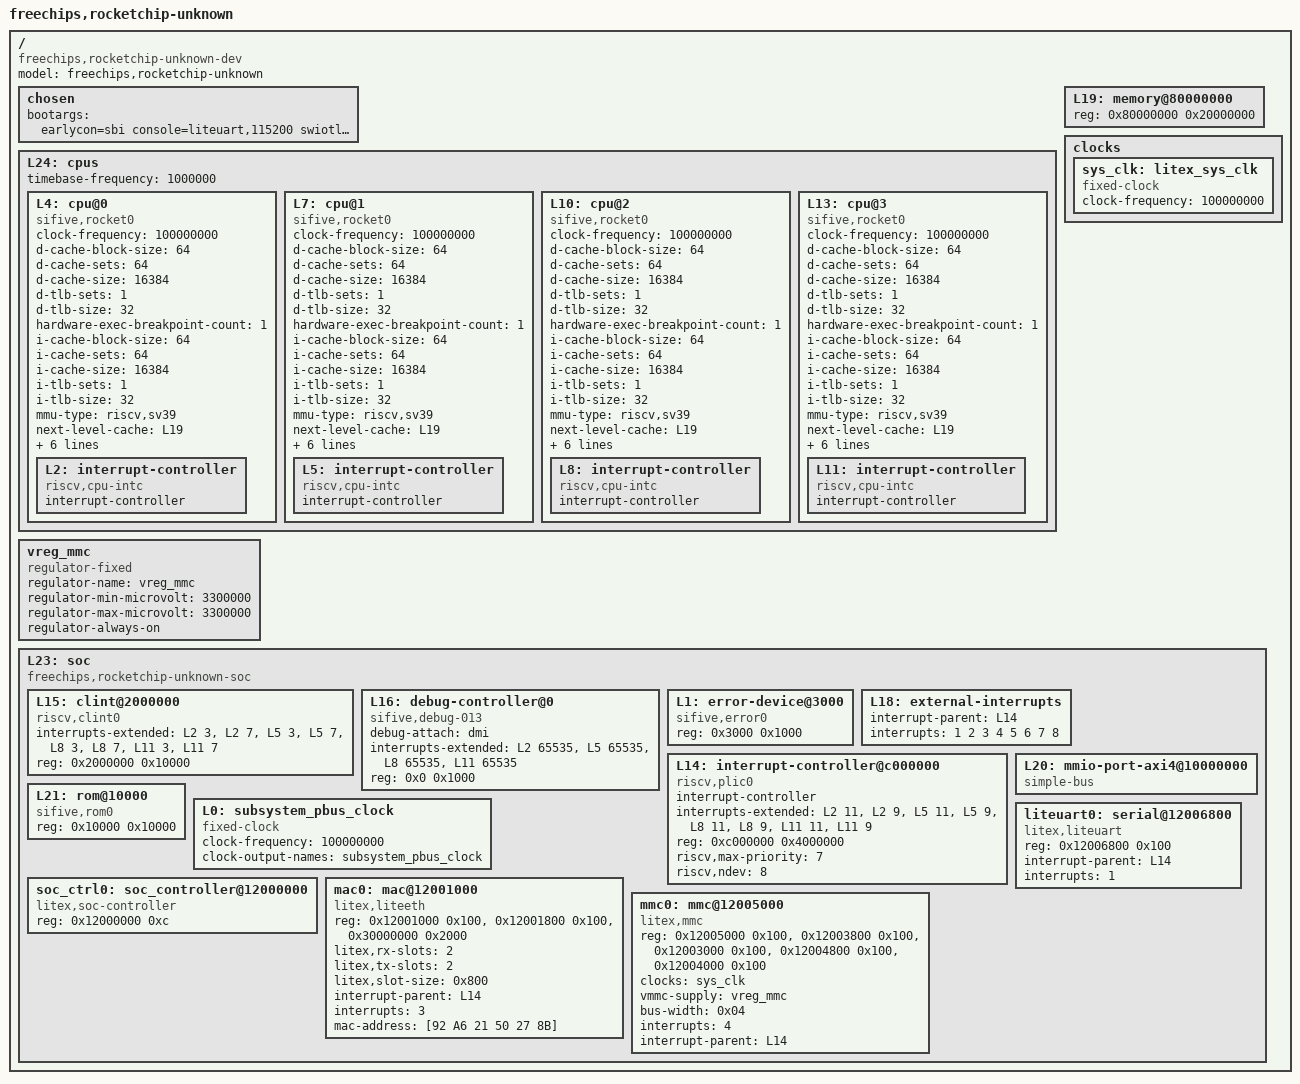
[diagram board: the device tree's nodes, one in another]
/dts-v1/;

/ {
	#address-cells = <1>;
	#size-cells = <1>;
	compatible = "freechips,rocketchip-unknown-dev";
	model = "freechips,rocketchip-unknown";
	chosen {
		bootargs = "earlycon=sbi console=liteuart,115200 swiotlb=noforce root=/dev/mmcblk0p2 rootwait";
	};
	L24: cpus {
		#address-cells = <1>;
		#size-cells = <0>;
		timebase-frequency = <1000000>;
		L4: cpu@0 {
			clock-frequency = <100000000>;
			compatible = "sifive,rocket0", "riscv";
			d-cache-block-size = <64>;
			d-cache-sets = <64>;
			d-cache-size = <16384>;
			d-tlb-sets = <1>;
			d-tlb-size = <32>;
			device_type = "cpu";
			hardware-exec-breakpoint-count = <1>;
			i-cache-block-size = <64>;
			i-cache-sets = <64>;
			i-cache-size = <16384>;
			i-tlb-sets = <1>;
			i-tlb-size = <32>;
			mmu-type = "riscv,sv39";
			next-level-cache = <&L19>;
			reg = <0x0>;
			riscv,isa = "rv64imafdc";
			riscv,pmpgranularity = <4>;
			riscv,pmpregions = <8>;
			status = "okay";
			timebase-frequency = <1000000>;
			tlb-split;
			L2: interrupt-controller {
				#interrupt-cells = <1>;
				compatible = "riscv,cpu-intc";
				interrupt-controller;
			};
		};
		L7: cpu@1 {
			clock-frequency = <100000000>;
			compatible = "sifive,rocket0", "riscv";
			d-cache-block-size = <64>;
			d-cache-sets = <64>;
			d-cache-size = <16384>;
			d-tlb-sets = <1>;
			d-tlb-size = <32>;
			device_type = "cpu";
			hardware-exec-breakpoint-count = <1>;
			i-cache-block-size = <64>;
			i-cache-sets = <64>;
			i-cache-size = <16384>;
			i-tlb-sets = <1>;
			i-tlb-size = <32>;
			mmu-type = "riscv,sv39";
			next-level-cache = <&L19>;
			reg = <0x1>;
			riscv,isa = "rv64imafdc";
			riscv,pmpgranularity = <4>;
			riscv,pmpregions = <8>;
			status = "okay";
			timebase-frequency = <1000000>;
			tlb-split;
			L5: interrupt-controller {
				#interrupt-cells = <1>;
				compatible = "riscv,cpu-intc";
				interrupt-controller;
			};
		};
		L10: cpu@2 {
			clock-frequency = <100000000>;
			compatible = "sifive,rocket0", "riscv";
			d-cache-block-size = <64>;
			d-cache-sets = <64>;
			d-cache-size = <16384>;
			d-tlb-sets = <1>;
			d-tlb-size = <32>;
			device_type = "cpu";
			hardware-exec-breakpoint-count = <1>;
			i-cache-block-size = <64>;
			i-cache-sets = <64>;
			i-cache-size = <16384>;
			i-tlb-sets = <1>;
			i-tlb-size = <32>;
			mmu-type = "riscv,sv39";
			next-level-cache = <&L19>;
			reg = <0x2>;
			riscv,isa = "rv64imafdc";
			riscv,pmpgranularity = <4>;
			riscv,pmpregions = <8>;
			status = "okay";
			timebase-frequency = <1000000>;
			tlb-split;
			L8: interrupt-controller {
				#interrupt-cells = <1>;
				compatible = "riscv,cpu-intc";
				interrupt-controller;
			};
		};
		L13: cpu@3 {
			clock-frequency = <100000000>;
			compatible = "sifive,rocket0", "riscv";
			d-cache-block-size = <64>;
			d-cache-sets = <64>;
			d-cache-size = <16384>;
			d-tlb-sets = <1>;
			d-tlb-size = <32>;
			device_type = "cpu";
			hardware-exec-breakpoint-count = <1>;
			i-cache-block-size = <64>;
			i-cache-sets = <64>;
			i-cache-size = <16384>;
			i-tlb-sets = <1>;
			i-tlb-size = <32>;
			mmu-type = "riscv,sv39";
			next-level-cache = <&L19>;
			reg = <0x3>;
			riscv,isa = "rv64imafdc";
			riscv,pmpgranularity = <4>;
			riscv,pmpregions = <8>;
			status = "okay";
			timebase-frequency = <1000000>;
			tlb-split;
			L11: interrupt-controller {
				#interrupt-cells = <1>;
				compatible = "riscv,cpu-intc";
				interrupt-controller;
			};
		};
	};
	L19: memory@80000000 {
		device_type = "memory";
		reg = <0x80000000 0x20000000>;
	};
	clocks {
            sys_clk: litex_sys_clk {
                #clock-cells = <0>;
                compatible = "fixed-clock";
                clock-frequency = <100000000>;
            };
        };

        vreg_mmc: vreg_mmc {
            compatible = "regulator-fixed";
            regulator-name = "vreg_mmc";
            regulator-min-microvolt = <3300000>;
            regulator-max-microvolt = <3300000>;
            regulator-always-on;
        };
	L23: soc {
		#address-cells = <1>;
		#size-cells = <1>;
		compatible = "freechips,rocketchip-unknown-soc", "simple-bus";
		ranges;
		L15: clint@2000000 {
			compatible = "riscv,clint0";
			interrupts-extended = <&L2 3 &L2 7 &L5 3 &L5 7 &L8 3 &L8 7 &L11 3 &L11 7>;
			reg = <0x2000000 0x10000>;
			reg-names = "control";
		};
		L16: debug-controller@0 {
			compatible = "sifive,debug-013", "riscv,debug-013";
			debug-attach = "dmi";
			interrupts-extended = <&L2 65535 &L5 65535 &L8 65535 &L11 65535>;
			reg = <0x0 0x1000>;
			reg-names = "control";
		};
		L1: error-device@3000 {
			compatible = "sifive,error0";
			reg = <0x3000 0x1000>;
		};
		L18: external-interrupts {
			interrupt-parent = <&L14>;
			interrupts = <1 2 3 4 5 6 7 8>;
		};
		L14: interrupt-controller@c000000 {
			#interrupt-cells = <1>;
			compatible = "riscv,plic0";
			interrupt-controller;
			interrupts-extended = <&L2 11 &L2 9 &L5 11 &L5 9 &L8 11 &L8 9 &L11 11 &L11 9>;
			reg = <0xc000000 0x4000000>;
			reg-names = "control";
			riscv,max-priority = <7>;
			riscv,ndev = <8>;
		};
		L20: mmio-port-axi4@10000000 {
			#address-cells = <1>;
			#size-cells = <1>;
			compatible = "simple-bus";
			ranges = <0x10000000 0x10000000 0x70000000>;
		};
		L21: rom@10000 {
			compatible = "sifive,rom0";
			reg = <0x10000 0x10000>;
			reg-names = "mem";
		};
		L0: subsystem_pbus_clock {
			#clock-cells = <0>;
			clock-frequency = <100000000>;
			clock-output-names = "subsystem_pbus_clock";
			compatible = "fixed-clock";
		};
		soc_ctrl0: soc_controller@12000000 {
			compatible = "litex,soc-controller";
			reg = <0x12000000 0xc>;
		};
		liteuart0: serial@12006800 {
			compatible = "litex,liteuart";
			reg = <0x12006800 0x100>;
			interrupt-parent = <&L14>;
			interrupts = <1>;
		};
		mac0: mac@12001000 {
			compatible = "litex,liteeth";
			reg = <0x12001000 0x100>,
				<0x12001800 0x100>,
				<0x30000000 0x2000>;
			reg-names = "mac", "mdio", "buffer";
			litex,rx-slots = <2>;
			litex,tx-slots = <2>;
			litex,slot-size = <0x800>;
			interrupt-parent = <&L14>;
			interrupts = <3>;
			mac-address = [92 A6 21 50 27 8B];
		};
		mmc0: mmc@12005000 {
		        compatible = "litex,mmc";
		        reg = <0x12005000 0x100>,
		              <0x12003800 0x100>,
		              <0x12003000 0x100>,
		              <0x12004800 0x100>,
		              <0x12004000 0x100>;
		        reg-names = "phy", "core", "reader", "writer", "irq";
		        clocks = <&sys_clk>;
			vmmc-supply = <&vreg_mmc>;
		        bus-width = <0x04>;
		        interrupts = <4>;
		        interrupt-parent = <&L14>;
		        status = "okay";
            	};
	};
};
